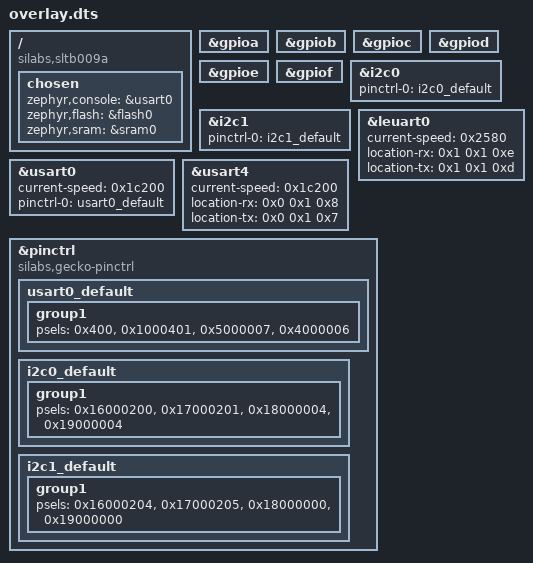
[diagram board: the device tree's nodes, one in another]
/ {
	compatible = "silabs,sltb009a";
	chosen {
		zephyr,console = &usart0;
		zephyr,flash = &flash0;
		zephyr,sram = &sram0;
	};
};
&gpioa{
	status = "okay";
};
&gpiob{
	status = "okay";
};
&gpioc{
	status = "okay";
};
&gpiod{
	status = "okay";
};
&gpioe{
	status = "okay";
};
&gpiof{
	status = "okay";
};
&i2c0{
	status = "okay";
	pinctrl-0 = < &i2c0_default >;
	pinctrl-names = "default";
};
&i2c1{
	status = "okay";
	pinctrl-0 = < &i2c1_default >;
	pinctrl-names = "default";
};
&leuart0{
	status = "okay";
	current-speed = < 0x2580 >;
	location-rx = < 0x1 0x1 0xe >;
	location-tx = < 0x1 0x1 0xd >;
};
&usart0{
	status = "okay";
	current-speed = < 0x1c200 >;
	pinctrl-0 = < &usart0_default >;
	pinctrl-names = "default";
};
&usart4{
	status = "okay";
	current-speed = < 0x1c200 >;
	location-rx = < 0x0 0x1 0x8 >;
	location-tx = < 0x0 0x1 0x7 >;
};
&pinctrl{
	compatible = "silabs,gecko-pinctrl";
	usart0_default: usart0_default {
		group1 {
			psels = < 0x400 >, < 0x1000401 >, < 0x5000007 >, < 0x4000006 >;
		};
	};
	i2c0_default: i2c0_default {
		group1 {
			psels = < 0x16000200 >, < 0x17000201 >, < 0x18000004 >, < 0x19000004 >;
		};
	};
	i2c1_default: i2c1_default {
		group1 {
			psels = < 0x16000204 >, < 0x17000205 >, < 0x18000000 >, < 0x19000000 >;
		};
	};
};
